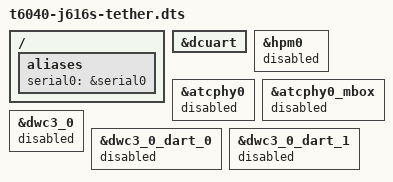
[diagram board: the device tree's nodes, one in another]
// SPDX-License-Identifier: GPL-2.0+ OR MIT
/* J616s tether console; the host owns ATC0 during the debug session. */
#include "t6040-j616s.dts"

/ {
	aliases {
		serial0 = &serial0;
	};
};

&dcuart {
	status = "okay";
};

&hpm0 {
	status = "disabled";
};

&atcphy0 {
	status = "disabled";
};

&atcphy0_mbox {
	status = "disabled";
};

&dwc3_0 {
	status = "disabled";
};

&dwc3_0_dart_0 {
	status = "disabled";
};

&dwc3_0_dart_1 {
	status = "disabled";
};
